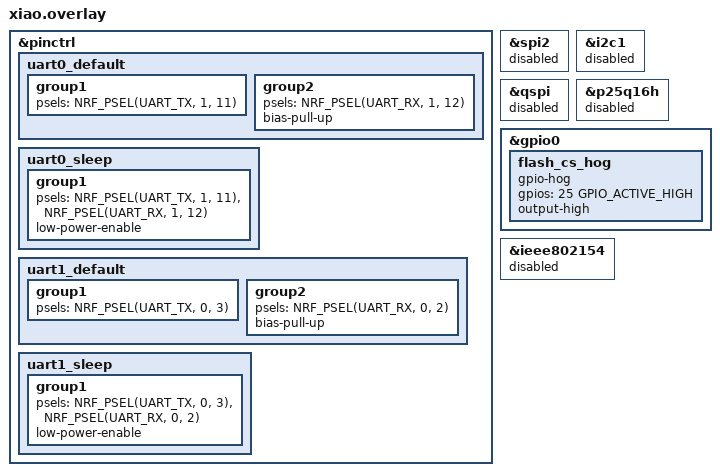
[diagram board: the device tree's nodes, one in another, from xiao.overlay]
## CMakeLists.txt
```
cmake_minimum_required(VERSION 3.20.0)

if(JC_LEFT)
  list(APPEND EXTRA_DTC_OVERLAY_FILE "${CMAKE_CURRENT_LIST_DIR}/left.overlay")
  list(APPEND EXTRA_CONF_FILE "${CMAKE_CURRENT_LIST_DIR}/left.conf")
endif()
# Pro Micro clones have no 32.768 kHz crystal, so they run the low frequency clock from the
# calibrated RC oscillator. The XIAO has the crystal (Zephyr's xiao_ble and Seeed's Arduino core
# both use it), so it uses that unless built with -DJC_CLOCK_RC=1.
if(JC_CLOCK_RC OR NOT BOARD MATCHES "^xiao_ble")
  list(APPEND EXTRA_DTC_OVERLAY_FILE "${CMAKE_CURRENT_LIST_DIR}/clock_rc.overlay")
  list(APPEND EXTRA_CONF_FILE "${CMAKE_CURRENT_LIST_DIR}/clock_rc.conf")
else()
  list(APPEND EXTRA_DTC_OVERLAY_FILE "${CMAKE_CURRENT_LIST_DIR}/clock_xtal.overlay")
endif()
if(NOT JC_LEFT)
  list(APPEND EXTRA_DTC_OVERLAY_FILE "${CMAKE_CURRENT_LIST_DIR}/right.overlay")
  list(APPEND EXTRA_CONF_FILE "${CMAKE_CURRENT_LIST_DIR}/usb_name_right.conf")
endif()
list(APPEND EXTRA_CONF_FILE "${CMAKE_CURRENT_LIST_DIR}/tx_power.conf")
# Seeed XIAO nRF52840 / Sense (-b xiao_ble): its own pins, applied last so they win
if(BOARD MATCHES "^xiao_ble")
  list(APPEND EXTRA_DTC_OVERLAY_FILE "${CMAKE_CURRENT_LIST_DIR}/xiao.overlay")
endif()

if(NOT DEFINED JC_OUT)
  set(JC_OUT "${CMAKE_CURRENT_LIST_DIR}/out")
endif()
if(JC_OUT)
  if(JC_LEFT)
    set(jc_uf2 "${JC_OUT}/xd2joy_LEFT.uf2")
  else()
    set(jc_uf2 "${JC_OUT}/xd2joy_RIGHT.uf2")
  endif()
  set_property(GLOBAL APPEND PROPERTY extra_post_build_commands
    COMMAND ${CMAKE_COMMAND} -E copy ${CMAKE_BINARY_DIR}/zephyr/zephyr.uf2 ${jc_uf2}
    COMMAND ${CMAKE_COMMAND} -E echo Firmware copied to ${jc_uf2})
endif()

find_package(Zephyr REQUIRED HINTS $ENV{ZEPHYR_BASE})
project(xd2joy)

file(READ "${ZEPHYR_BASE}/include/zephyr/bluetooth/hci_types.h" jc_hci)
string(REGEX MATCH "#define[ \t]+BT_HCI_LE_INTERVAL_MIN[ \t]+0x0004" jc_floor "${jc_hci}")
if(NOT jc_floor)
  message(FATAL_ERROR "Zephyr patch 1 is missing: BT_HCI_LE_INTERVAL_MIN in "
                      "include/zephyr/bluetooth/hci_types.h is not 0x0004 -- see "
                      "ZEPHYR_PATCHES.md at the top of this repository")
endif()

foreach(jc_patched
    subsys/bluetooth/controller/ll_sw/nordic/lll/lll_scan.c
    subsys/bluetooth/controller/ll_sw/ull_llcp_conn_upd.c)
  file(READ "${ZEPHYR_BASE}/${jc_patched}" jc_src)
  string(FIND "${jc_src}" "conn window patch" jc_at)
  if(jc_at EQUAL -1)
    message(FATAL_ERROR "Zephyr patch 2 is missing from ${jc_patched} -- see "
                        "ZEPHYR_PATCHES.md at the top of this repository")
  endif()
endforeach()
zephyr_compile_definitions(JC_CONN_WIN_OFFSET=4 JC_CONN_WIN_SIZE=3)

# reported by the `ver` console command; the desktop tool shows it and compares
# it with the firmware it bundles
execute_process(
  COMMAND git describe --tags --always --dirty
  WORKING_DIRECTORY ${CMAKE_CURRENT_LIST_DIR}
  OUTPUT_VARIABLE jc_version
  OUTPUT_STRIP_TRAILING_WHITESPACE
  ERROR_QUIET
  RESULT_VARIABLE jc_version_rc)
if(NOT jc_version_rc EQUAL 0 OR NOT jc_version)
  set(jc_version "dev")
endif()
zephyr_compile_definitions(XD2JOY_FW_VERSION="${jc_version}")

# keeps the crash record where the bootloader leaves it alone (see the file)
zephyr_linker_sources(NOINIT noinit_first.ld)

target_sources(app PRIVATE
    src/chip_addr.c
    src/console_keep.c
    src/main.c
    src/bridge.c
    src/hci_user_ext.c)
target_include_directories(app PRIVATE
    ${ZEPHYR_BASE}/subsys/bluetooth/controller
    ${ZEPHYR_BASE}/subsys/bluetooth/controller/ll_sw/nordic)
target_include_directories(app PRIVATE ${ZEPHYR_BASE}/subsys/bluetooth)
zephyr_include_directories(src)

if(JC_LEFT)
  target_compile_definitions(app PRIVATE JC_LEFT=1)
  target_sources(app PRIVATE src/usb_dev.c)
endif()
```

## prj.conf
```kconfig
CONFIG_BT=y
CONFIG_BT_PERIPHERAL=y
CONFIG_BT_DEVICE_NAME="Joy-Con 2 (R)"

CONFIG_BT_L2CAP_TX_MTU=512
CONFIG_BT_BUF_ACL_RX_SIZE=520
CONFIG_BT_BUF_ACL_TX_SIZE=251
CONFIG_BT_ATT_PREPARE_COUNT=2

CONFIG_BT_GATT_SERVICE_CHANGED=n
CONFIG_BT_GATT_CACHING=n

CONFIG_PRINTK=y

CONFIG_BT_GAP_PERIPHERAL_PREF_PARAMS=n

CONFIG_BT_HCI_VS=y
CONFIG_BT_DEVICE_NAME="Joy-Con 2 (R)"

CONFIG_BT_CTLR_TX_PWR_PLUS_4=y

CONFIG_BT_CTLR_CONN_INTERVAL_LOW_LATENCY=n
CONFIG_BT_CONN_PARAM_ANY=y
CONFIG_BT_CTLR_ADVANCED_FEATURES=y
CONFIG_BT_GAP_AUTO_UPDATE_CONN_PARAMS=n

CONFIG_BT_SMP=y

CONFIG_BT_GATT_CLIENT=y
CONFIG_BT_GATT_AUTO_UPDATE_MTU=n

CONFIG_BT_CTLR_DATA_LENGTH_MAX=251

CONFIG_BT_CTLR_USER_EXT=y
CONFIG_BT_CTLR_USER_CPR_INTERVAL_MIN=y

CONFIG_BT_CENTRAL=y
CONFIG_BT_OBSERVER=y
CONFIG_BT_MAX_CONN=2
CONFIG_BT_MAX_PAIRED=2
CONFIG_BT_GATT_AUTO_DISCOVER_CCC=y

CONFIG_BT_SMP_ENFORCE_MITM=n

CONFIG_BT_SMP_SC_PAIR_ONLY=n

CONFIG_LOG=n
CONFIG_BT_SMP_LOG_LEVEL_DBG=n

CONFIG_BT_SCAN_WITH_IDENTITY=y

CONFIG_BT_RX_STACK_SIZE=3072
CONFIG_MAIN_STACK_SIZE=2048
CONFIG_SYSTEM_WORKQUEUE_STACK_SIZE=3072

CONFIG_THREAD_ANALYZER=n
CONFIG_RESET_ON_FATAL_ERROR=n

CONFIG_SERIAL=y
CONFIG_UART_INTERRUPT_DRIVEN=y

CONFIG_BT_ATT_TX_COUNT=10

CONFIG_BT_BUF_ACL_TX_COUNT=12
CONFIG_BT_L2CAP_TX_BUF_COUNT=12
CONFIG_BT_BUF_EVT_RX_COUNT=16

CONFIG_BT_SETTINGS=y
CONFIG_FLASH=y
CONFIG_FLASH_MAP=y
CONFIG_FLASH_PAGE_LAYOUT=y
CONFIG_NVS=y
CONFIG_SETTINGS=y

CONFIG_MPU_ALLOW_FLASH_WRITE=y

# USB host bridge on UART1: DMA (async) receive, the other UARTs stay
# interrupt driven
CONFIG_UART_ASYNC_API=y
CONFIG_UART_1_INTERRUPT_DRIVEN=n
CONFIG_UART_1_ASYNC=y
CONFIG_UART_1_NRF_ASYNC_LOW_POWER=n
# noinit_first.ld goes at the start of .noinit (it holds the crash record)
CONFIG_NOINIT_SNIPPET_FIRST=y
```

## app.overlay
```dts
&uicr {
	nfct-pins-as-gpios;
};

#include <zephyr/dt-bindings/pinctrl/nrf-pinctrl.h>

&pinctrl {
	uart0_default: uart0_default {
		group1 {
			psels = <NRF_PSEL(UART_TX, 0, 9)>;
		};
		group2 {
			psels = <NRF_PSEL(UART_RX, 0, 10)>;
			bias-pull-up;
		};
	};

	uart0_sleep: uart0_sleep {
		group1 {
			psels = <NRF_PSEL(UART_TX, 0, 9)>,
				<NRF_PSEL(UART_RX, 0, 10)>;
			low-power-enable;
		};
	};
};

/*
 * UART1: input from the USB host bridge (bridge/ in this repo).
 * P0.08 is RX, the pin marked RX/D0 on Pro Micro style boards. P0.06 (TX/D1)
 * is reserved for a future back channel; nothing reads it yet.
 */
&pinctrl {
	uart1_default: uart1_default {
		group1 {
			psels = <NRF_PSEL(UART_TX, 0, 6)>;
		};
		group2 {
			psels = <NRF_PSEL(UART_RX, 0, 8)>;
			bias-pull-up;
		};
	};

	uart1_sleep: uart1_sleep {
		group1 {
			psels = <NRF_PSEL(UART_TX, 0, 6)>,
				<NRF_PSEL(UART_RX, 0, 8)>;
			low-power-enable;
		};
	};
};

&uart1 {
	status = "okay";
	current-speed = <1000000>;
	pinctrl-0 = <&uart1_default>;
	pinctrl-1 = <&uart1_sleep>;
	pinctrl-names = "default", "sleep";
};
```

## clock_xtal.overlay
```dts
/* Seeed XIAO nRF52840: its 32.768 kHz crystal. These are Zephyr's defaults, spelled out so the
 * build script can check them; 50 ppm is the conservative class for a plain watch crystal. */
&lfclk {
	k32src = "xtal";
	k32src-accuracy-ppm = <50>;
};
```

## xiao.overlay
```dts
/*
 * Seeed XIAO nRF52840 (and Sense): build with -b xiao_ble.
 *
 * Added after left.overlay / right.overlay, so these pins win over the Pro Micro ones there.
 * Both halves use the same pins on this board:
 *
 *   board link (UART0)   TX = D6 (P1.11)   RX = D7 (P1.12)   the pads marked TX and RX
 *   USB host bridge in   RX = D0 (P0.02)   TX = D1 (P0.03, reserved, nothing reads it yet)
 *
 * The Pro Micro bridge pins (P0.06, P0.08) are not on the XIAO's edge, and P0.06 is its blue LED.
 */

#include <zephyr/dt-bindings/gpio/gpio.h>
#include <zephyr/dt-bindings/pinctrl/nrf-pinctrl.h>

&pinctrl {
	uart0_default: uart0_default {
		group1 {
			psels = <NRF_PSEL(UART_TX, 1, 11)>;
		};
		group2 {
			psels = <NRF_PSEL(UART_RX, 1, 12)>;
			bias-pull-up;
		};
	};

	uart0_sleep: uart0_sleep {
		group1 {
			psels = <NRF_PSEL(UART_TX, 1, 11)>,
				<NRF_PSEL(UART_RX, 1, 12)>;
			low-power-enable;
		};
	};

	uart1_default: uart1_default {
		group1 {
			psels = <NRF_PSEL(UART_TX, 0, 3)>;
		};
		group2 {
			psels = <NRF_PSEL(UART_RX, 0, 2)>;
			bias-pull-up;
		};
	};

	uart1_sleep: uart1_sleep {
		group1 {
			psels = <NRF_PSEL(UART_TX, 0, 3)>,
				<NRF_PSEL(UART_RX, 0, 2)>;
			low-power-enable;
		};
	};
};

/* Not used by this firmware; off so their drivers stay out of the image and off the pins. */
&spi2 {
	status = "disabled";
};

&i2c1 {
	status = "disabled";
};

&qspi {
	status = "disabled";
};

/* The flash chip node stays "okay" under a disabled &qspi, and that alone builds and starts the
 * QSPI flash driver (Zephyr instantiates nodes by their own status), so turn the chip off too. */
&p25q16h {
	status = "disabled";
};

/* With the flash driver gone nothing drives the chip's chip select (P0.25). Hold it high, chip
 * deselected, as Seeed's own Arduino core does at boot, rather than leave it floating. */
&gpio0 {
	flash_cs_hog {
		gpio-hog;
		gpios = <25 GPIO_ACTIVE_HIGH>;
		output-high;
	};
};

&ieee802154 {
	status = "disabled";
};
```

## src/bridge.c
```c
#include <zephyr/kernel.h>
#include <zephyr/device.h>
#include <zephyr/drivers/uart.h>
#include <zephyr/sys/byteorder.h>
#include <string.h>

#include "bridge.h"
#include "bridge_proto.h"

/*
 * UART1 uses the async (DMA) API: at 1 Mbaud a byte arrives every 10 us,
 * which the one-byte interrupt-driven mode can't keep up with while the
 * radio ISRs run. Bytes land in DMA buffers and are parsed in the callback.
 */
#define BR_NODE DT_NODELABEL(uart1)
#define BR_BUF_LEN 64
#define BR_RX_TIMEOUT_US 100

struct br_msg {
	uint8_t type;
	uint8_t len;
	uint8_t p[JC_BR_MAX_PAYLOAD];
};

K_MSGQ_DEFINE(br_q, sizeof(struct br_msg), 32, 4);

static const struct device *const br_uart = DEVICE_DT_GET(BR_NODE);
static uint8_t br_buf[2][BR_BUF_LEN];
static uint8_t br_next;

static uint8_t br_f[JC_BR_MAX_PAYLOAD + JC_BR_OVERHEAD];
static uint8_t br_n;

static atomic_t br_good;
static atomic_t br_bad;
static atomic_t br_devs;

uint8_t jc_bridge_devices(void)
{
	return (uint8_t)atomic_get(&br_devs);
}

uint32_t jc_bridge_frames(void)
{
	return (uint32_t)atomic_get(&br_good);
}

uint32_t jc_bridge_bad_frames(void)
{
	return (uint32_t)atomic_get(&br_bad);
}

static void br_feed(const uint8_t *d, size_t n)
{
	for (size_t i = 0; i < n; i++) {
		uint8_t c = d[i];

		if (br_n == 0) {
			if (c == JC_BR_SYNC) {
				br_f[br_n++] = c;
			}
			continue;
		}
		if (br_n == 2 && c > JC_BR_MAX_PAYLOAD) {
			/* impossible length: resync, maybe on this byte */
			br_n = 0;
			atomic_inc(&br_bad);
			if (c == JC_BR_SYNC) {
				br_f[br_n++] = c;
			}
			continue;
		}
		br_f[br_n++] = c;
		if (br_n < 3 || br_n < (size_t)br_f[2] + JC_BR_OVERHEAD) {
			continue;
		}

		uint8_t len = br_f[2];

		br_n = 0;
		if (jc_br_crc8(&br_f[1], (size_t)len + 2) != br_f[3 + len]) {
			atomic_inc(&br_bad);
			continue;
		}

		struct br_msg m = { .type = br_f[1], .len = len };

		memcpy(m.p, &br_f[3], len);
		if (k_msgq_put(&br_q, &m, K_NO_WAIT) == 0) {
			atomic_inc(&br_good);
		} else {
			atomic_inc(&br_bad);
		}
	}
}

static void br_rx_start(void);

static void br_restart_fn(struct k_work *w)
{
	ARG_UNUSED(w);
	br_rx_start();
}
static K_WORK_DELAYABLE_DEFINE(br_restart, br_restart_fn);

static void br_uart_cb(const struct device *dev, struct uart_event *evt,
		       void *user_data)
{
	ARG_UNUSED(user_data);

	switch (evt->type) {
	case UART_RX_RDY:
		br_feed(evt->data.rx.buf + evt->data.rx.offset, evt->data.rx.len);
		break;
	case UART_RX_BUF_REQUEST:
		if (uart_rx_buf_rsp(dev, br_buf[br_next], BR_BUF_LEN) == 0) {
			br_next ^= 1U;
		}
		break;
	case UART_RX_STOPPED:
		/* framing/overrun error; the frame in progress is garbage */
		br_n = 0;
		atomic_inc(&br_bad);
		break;
	case UART_RX_DISABLED:
		/* after an error the driver stops RX; bring it back */
		k_work_schedule(&br_restart, K_MSEC(5));
		break;
	default:
		break;
	}
}

static void br_rx_start(void)
{
	int err;

	br_n = 0;
	br_next = 1;
	err = uart_rx_enable(br_uart, br_buf[0], BR_BUF_LEN, BR_RX_TIMEOUT_US);
	if (err && err != -EBUSY) {
		k_work_schedule(&br_restart, K_MSEC(100));
	}
}

static void br_set_devices(uint8_t devs)
{
	uint8_t was = (uint8_t)atomic_set(&br_devs, devs);

	if (was != devs) {
		jc_bridge_changed(devs);
	}
}

static void br_dispatch(const struct br_msg *m)
{
	switch (m->type) {
	case JC_BR_KBD:
		if (m->len >= JC_BR_KBD_LEN) {
			jc_bridge_kbd(m->p[0], &m->p[1]);
		}
		break;
	case JC_BR_MOUSE:
		if (m->len >= JC_BR_MOUSE_LEN) {
			jc_bridge_mouse((int16_t)sys_get_le16(&m->p[1]),
					(int16_t)sys_get_le16(&m->p[3]),
					(int8_t)m->p[5], m->p[0]);
		}
		break;
	case JC_BR_STATUS:
		if (m->len >= JC_BR_STATUS_LEN && m->p[0] == JC_BR_PROTO_VER) {
			br_set_devices(m->p[1] & (JC_BR_HAS_KBD | JC_BR_HAS_MOUSE));
		}
		break;
	default:
		break;
	}
}

static void br_thread(void *a, void *b, void *c)
{
	int64_t last_status = 0;

	ARG_UNUSED(a); ARG_UNUSED(b); ARG_UNUSED(c);

	if (!device_is_ready(br_uart)) {
		return;
	}
	if (uart_callback_set(br_uart, br_uart_cb, NULL)) {
		return;
	}
	br_rx_start();

	while (1) {
		struct br_msg m;

		if (k_msgq_get(&br_q, &m, K_MSEC(JC_BR_STATUS_MS)) == 0) {
			if (m.type == JC_BR_STATUS) {
				last_status = k_uptime_get();
			}
			br_dispatch(&m);
		}
		if (atomic_get(&br_devs) &&
		    k_uptime_get() - last_status > JC_BR_LOST_MS) {
			br_set_devices(0);
		}
	}
}

/* Cooperative and just below the BT RX thread (CONFIG_BT_RX_PRIO = 8). */
K_THREAD_DEFINE(br_tid, 3072, br_thread, NULL, NULL, NULL,
		K_PRIO_COOP(9), 0, 0);
```

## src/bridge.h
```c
#ifndef XD2JOY_BRIDGE_H_
#define XD2JOY_BRIDGE_H_

#include <stdbool.h>
#include <stdint.h>

/* UART receiver for the USB host bridge (bridge/ in this repo). */

/* JC_BR_HAS_* flags from the last status frame, 0 when the bridge is silent. */
uint8_t jc_bridge_devices(void);
uint32_t jc_bridge_frames(void);
uint32_t jc_bridge_bad_frames(void);

/*
 * Implemented in main.c. Called from the bridge thread, which is cooperative
 * like the Bluetooth RX thread, so they see the same guarantees the BLE
 * notify path does.
 */
void jc_bridge_kbd(uint8_t mods, const uint8_t keys[6]);
void jc_bridge_mouse(int16_t dx, int16_t dy, int8_t wheel, uint8_t buttons);
/* devices changed; main.c releases held input when its device goes away */
void jc_bridge_changed(uint8_t devices);

#endif /* XD2JOY_BRIDGE_H_ */
```

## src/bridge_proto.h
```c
/*
 * Wire format between the USB host bridge (bridge/) and each nRF52840.
 * Shared verbatim by both firmwares, so change it in one place only.
 *
 * Frame: SYNC | TYPE | LEN | PAYLOAD[LEN] | CRC8(TYPE..PAYLOAD)
 * CRC-8 poly 0x07, init 0x00, MSB first (same as the board-to-board link).
 * One UART per nRF: the bridge sends keyboard frames to the left board and
 * mouse frames to the right board, and status frames to both.
 */
#ifndef XD2JOY_BRIDGE_PROTO_H_
#define XD2JOY_BRIDGE_PROTO_H_

#include <stdint.h>
#include <stddef.h>

#define JC_BR_BAUD 1000000

#define JC_BR_SYNC 0xC3
#define JC_BR_MAX_PAYLOAD 12
#define JC_BR_OVERHEAD 4 /* sync, type, len, crc */

#define JC_BR_PROTO_VER 1

/* mods, keys[6] (boot keyboard layout, usage page 0x07) */
#define JC_BR_KBD 0x01
#define JC_BR_KBD_LEN 7

/* buttons, dx (i16 LE), dy (i16 LE), wheel (i8). dx/dy/wheel are deltas
 * accumulated since the previous mouse frame; buttons is the full state.
 */
#define JC_BR_MOUSE 0x02
#define JC_BR_MOUSE_LEN 6

/* version, flags, devices. Sent every JC_BR_STATUS_MS; a board that hears
 * nothing for JC_BR_LOST_MS treats the bridge as gone and releases input.
 */
#define JC_BR_STATUS 0x03
#define JC_BR_STATUS_LEN 3
#define JC_BR_HAS_KBD 0x01
#define JC_BR_HAS_MOUSE 0x02

#define JC_BR_STATUS_MS 100
#define JC_BR_LOST_MS 500

static inline uint8_t jc_br_crc8(const uint8_t *p, size_t n)
{
	uint8_t crc = 0;

	while (n--) {
		crc ^= *p++;
		for (int i = 0; i < 8; i++) {
			crc = (crc & 0x80) ? (uint8_t)((crc << 1) ^ 0x07)
					   : (uint8_t)(crc << 1);
		}
	}
	return crc;
}

#endif /* XD2JOY_BRIDGE_PROTO_H_ */
```
